# GD32EPRT register map
File version: 1.0
CPU: CM33 r0p4, little endian, MPU, FPU, 4 interrupt priority bits
Registers are 32-bit, read-write, reset 0x0 unless marked. A register's access mark holds for its fields unless they carry their own. Offsets are from the block's base; [hi:lo] are bit positions.

## WWDGT — Window watchdog timer
Base 0x40002C00
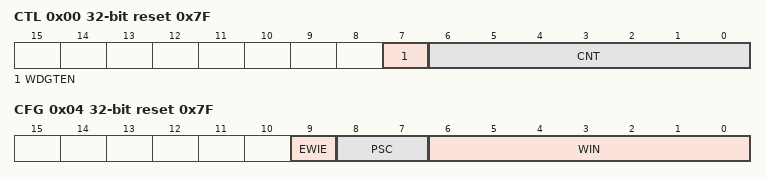
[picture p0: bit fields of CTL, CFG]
0x00 CTL reset 0x7F — Control register
  [7] WDGTEN — Activation bit
  [6:0] CNT — 7-bit counter
0x04 CFG reset 0x7F — Configuration register
  [9] EWIE — Early wakeup interrupt
  [8:7] PSC — Prescaler
  [6:0] WIN — 7-bit window value
0x08 STAT — Status register
  [0] EWIF — Early wakeup interrupt flag

## ENET_MAC_FCTH — MAC flow control threshold register
Base 0x40029080
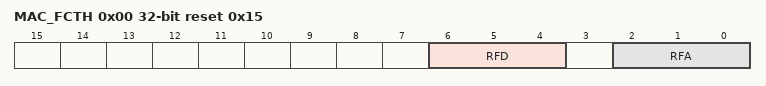
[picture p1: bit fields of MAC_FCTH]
0x00 MAC_FCTH reset 0x15 — Ethernet MAC flow control threshold register
  [6:4] RFD — Threshold of deactive flow control
  [2:0] RFA — Threshold of active flow control

## ENET_MSC — Ethernet: MAC statistics counters
Base 0x40028100
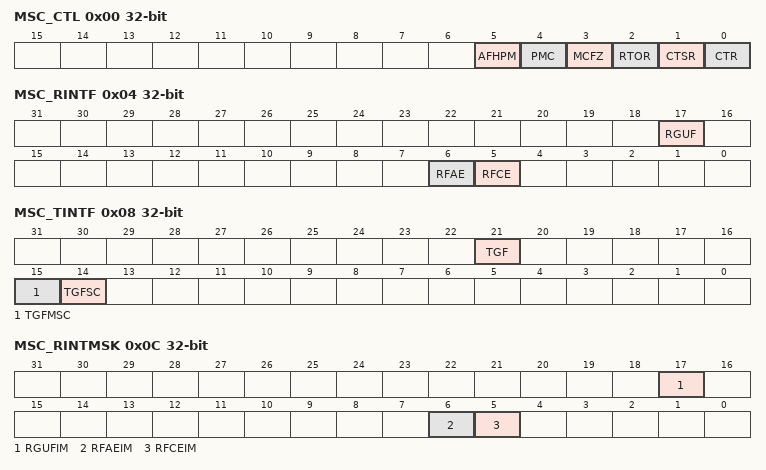
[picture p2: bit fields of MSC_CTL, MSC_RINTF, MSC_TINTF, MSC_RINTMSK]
0x00 MSC_CTL — Ethernet MSC control register (MSC_CTL)
  [5] AFHPM — Almost full or half preset mode
  [4] PMC wo — Preset MSC counter
  [3] MCFZ — MSC counter freeze
  [2] RTOR — Reset on read
  [1] CTSR — Counter stop rollover
  [0] CTR — Counter reset
0x04 MSC_RINTF ro — Ethernet MSC receive interrupt flag register (MSC_RINTF)
  [17] RGUF — Received Good Unicast Frames
  [6] RFAE — Received frames alignment error
  [5] RFCE — Received frames CRC error
0x08 MSC_TINTF ro — Ethernet MSC transmit interrupt flag register (MSC_TINTF)
  [21] TGF — Transmitted good frames
  [15] TGFMSC — Transmitted good frames more single collision
  [14] TGFSC — Transmitted good frames single collision
0x0C MSC_RINTMSK — Ethernet MSC receive interrupt mask register (MSC_RINTMSK)
  [17] RGUFIM — Received good unicast frames interrupt mask
  [6] RFAEIM — Received frames alignment error interrupt mask
  [5] RFCEIM — Received frame CRC error interrupt mask
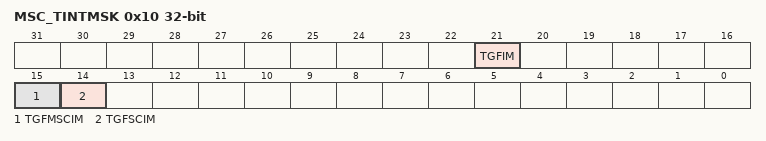
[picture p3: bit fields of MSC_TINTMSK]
0x10 MSC_TINTMSK — Ethernet MSC transmit interrupt mask register (MSC_TINTMSK)
  [21] TGFIM — Transmitted good frames interrupt mask
  [15] TGFMSCIM — Transmitted good frames more single interrupt collision mask
  [14] TGFSCIM — Transmitted good frames single collision interrupt mask
0x4C MSC_SCCNT ro — Ethernet MSC transmitted good frames after a single collision counter
  [31:0] SCC — Transmitted good frames after a single collision counter
0x50 MSC_MSCCNT ro — Ethernet MSC transmitted good frames after more than a single collision
  [31:0] MSCC — Transmitted good frames after more than a single collision counter
0x68 MSC_TGFCNT ro — Ethernet MSC transmitted good frames counter register
  [31:0] TGF — Transmitted good frames counter
0x94 MSC_RFCECNT ro — Ethernet MSC received frames with CRC error counter register
  [31:0] RFCER — Received frames with CRC error counter
0x98 MSC_RFAECNT ro — Ethernet MSC received frames with alignment error counter register
  [31:0] RFAER — Received frames with alignment error counter
0xC4 MSC_RGUFCNT ro — MSC received good unicast frames counter register
  [31:0] RGUF — Received good unicast frames counter

## ENET_PTP — Ethernet: Precision time protocol
Base 0x40028700
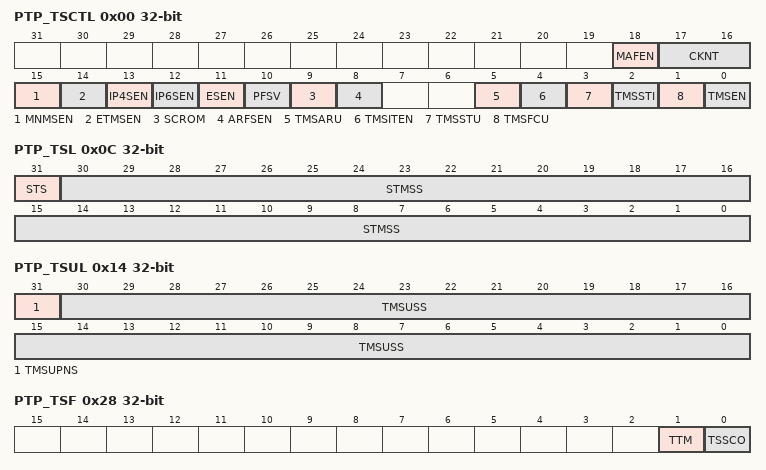
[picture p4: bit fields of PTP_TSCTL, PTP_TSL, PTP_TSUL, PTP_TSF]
0x00 PTP_TSCTL — Ethernet PTP time stamp control register (PTP_TSCTL)
  [18] MAFEN — MAC address filter enable for PTP frame
  [17:16] CKNT — Clock node type for time stamp
  [15] MNMSEN — Received master node message snapshot enable
  [14] ETMSEN — Received event type message snapshot enable
  [13] IP4SEN — Received IPv4 snapshot enable
  [12] IP6SEN — Received IPv6 snapshot enable
  [11] ESEN — Received Ethernet snapshot enable
  [10] PFSV — PTP frame snooping version
  [9] SCROM — Subsecond counter rollover mode
  [8] ARFSEN — All received frames snapshot enable
  [5] TMSARU — Time stamp addend register update
  [4] TMSITEN — Time stamp interrupt trigger enable
  [3] TMSSTU — Time stamp system time update
  [2] TMSSTI — Time stamp system time initialize
  [1] TMSFCU — Time stamp fine or coarse update
  [0] TMSEN — Time stamp enable
0x04 PTP_SSINC — Ethernet PTP subsecond increment register
  [7:0] STMSSI — System time subsecond increment
0x08 PTP_TSH ro — Ethernet PTP time stamp high register
  [31:0] STMS — System time second
0x0C PTP_TSL ro — Ethernet PTP time stamp low register (PTP_TSL)
  [31] STS — System time sign
  [30:0] STMSS — System time subseconds
0x10 PTP_TSUH — Ethernet PTP time stamp high update register
  [31:0] TMSUS — Time stamp update second
0x14 PTP_TSUL — Ethernet PTP time stamp low update register (PTP_TSUL)
  [31] TMSUPNS — Time stamp update positive or negative sign
  [30:0] TMSUSS — Time stamp update subseconds
0x18 PTP_TSADDEND — Ethernet PTP time stamp addend register
  [31:0] TMSA — Time stamp addend
0x1C PTP_ETH — Ethernet PTP expected time high register
  [31:0] ETSH — Expected time stamp high
0x20 PTP_ETL — Ethernet PTP expected time low register
  [31:0] ETSL — Expected time stamp low
0x28 PTP_TSF ro — Ethernet PTP time stamp flag register
  [1] TTM — Target time match
  [0] TSSCO — Timestamp second counter overflow
0x2C PTP_PPSCTL — Ethernet PTP PPS control register
  [3:0] PPSOFC — PPS output frequency configure
